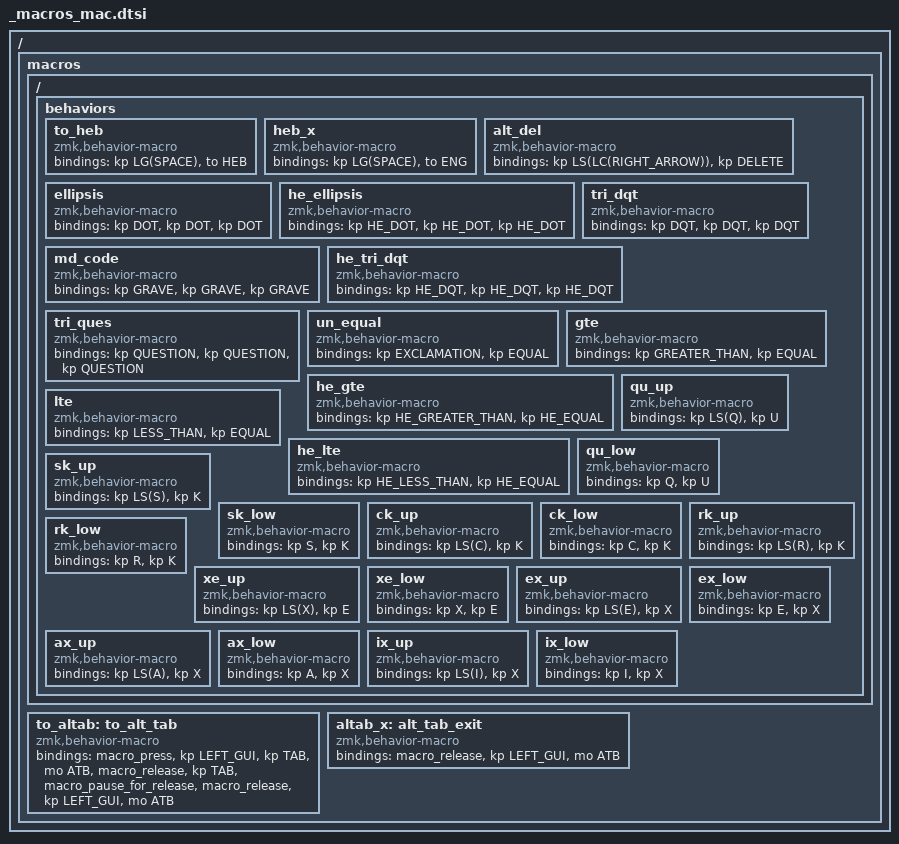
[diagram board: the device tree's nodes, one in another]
/ {
    macros {
        ZMK_MACRO(to_heb,
            bindings = <&kp LG(SPACE) &to HEB>;
        )

        ZMK_MACRO(heb_x,
            bindings = <&kp LG(SPACE) &to ENG>;
        )

        // Source: Discord
        // Author: Kites&Darts
        // https://discord.com/channels/719497620560543766/719909884769992755/1174453126716198942
        // https://github.com/damunchkn/zmk-config-fseli/blob/master/config/cradio.keymap
        to_altab: to_alt_tab {
            compatible = "zmk,behavior-macro";
            #binding-cells = <0>;
            bindings =
                <&macro_press &kp LEFT_GUI &kp TAB &mo ATB>,
                <&macro_release &kp TAB>,
                <&macro_pause_for_release>,
                <&macro_release &kp LEFT_GUI &mo ATB>;
        };

        altab_x: alt_tab_exit {
            compatible = "zmk,behavior-macro";
            #binding-cells = <0>;
            bindings = <&macro_release>, <&kp LEFT_GUI &mo ATB>;
        };

        // delete_next_word
        ZMK_MACRO(alt_del,
            bindings = <&kp LS(LC(RIGHT_ARROW)) &kp DELETE>;
        )

        ZMK_MACRO(ellipsis,
            bindings = <&kp DOT &kp DOT &kp DOT>;
        )

        ZMK_MACRO(he_ellipsis,
            bindings = <&kp HE_DOT &kp HE_DOT &kp HE_DOT>;
        )

        ZMK_MACRO(md_code,
            bindings = <&kp GRAVE &kp GRAVE &kp GRAVE>;
        )

        ZMK_MACRO(tri_dqt,
            bindings = <&kp DQT &kp DQT &kp DQT>;
        )

        ZMK_MACRO(he_tri_dqt,
            bindings = <&kp HE_DQT &kp HE_DQT &kp HE_DQT>;
        )

        // triple_question
        ZMK_MACRO(tri_ques,
            bindings = <&kp QUESTION &kp QUESTION &kp QUESTION>;
        )

        // exclamation_equal
        ZMK_MACRO(un_equal,
            bindings = <&kp EXCLAMATION &kp EQUAL>;
        )

        ZMK_MACRO(gte,
            bindings = <&kp GREATER_THAN &kp EQUAL>;
        )

        ZMK_MACRO(he_gte,
            bindings = <&kp HE_GREATER_THAN &kp HE_EQUAL>;
        )

        ZMK_MACRO(lte,
            bindings = <&kp LESS_THAN &kp EQUAL>;
        )

        ZMK_MACRO(he_lte,
            bindings = <&kp HE_LESS_THAN &kp HE_EQUAL>;
        )

        // Letter Combinations
        ZMK_MACRO(qu_up,
            bindings = <&kp LS(Q) &kp U>;
        )

        ZMK_MACRO(qu_low,
            bindings = <&kp Q &kp U>;
        )

        ZMK_MACRO(sk_up,
            bindings = <&kp LS(S) &kp K>;
        )

        ZMK_MACRO(sk_low,
            bindings = <&kp S &kp K>;
        )

        ZMK_MACRO(ck_up,
            bindings = <&kp LS(C) &kp K>;
        )

        ZMK_MACRO(ck_low,
            bindings = <&kp C &kp K>;
        )

        ZMK_MACRO(rk_up,
            bindings = <&kp LS(R) &kp K>;
        )

        ZMK_MACRO(rk_low,
            bindings = <&kp R &kp K>;
        )

        ZMK_MACRO(xe_up,
            bindings = <&kp LS(X) &kp E>;
        )

        ZMK_MACRO(xe_low,
            bindings = <&kp X &kp E>;
        )

        ZMK_MACRO(ex_up,
            bindings = <&kp LS(E) &kp X>;
        )

        ZMK_MACRO(ex_low,
            bindings = <&kp E &kp X>;
        )

        ZMK_MACRO(ax_up,
            bindings = <&kp LS(A) &kp X>;
        )

        ZMK_MACRO(ax_low,
            bindings = <&kp A &kp X>;
        )

        ZMK_MACRO(ix_up,
            bindings = <&kp LS(I) &kp X>;
        )

        ZMK_MACRO(ix_low,
            bindings = <&kp I &kp X>;
        )
    };
};
